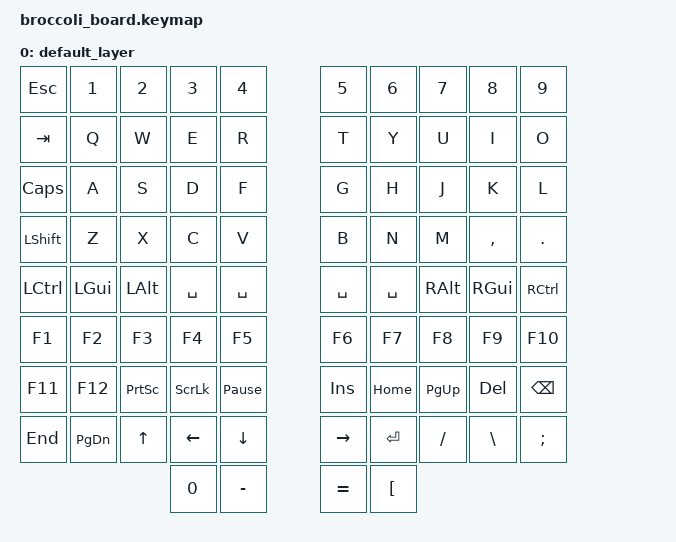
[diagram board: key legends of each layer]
#include <behaviors.dtsi>
#include <dt-bindings/zmk/keys.h>

/ {
    keymap {
        compatible = "zmk,keymap";
        default_layer {
            bindings = 
                &kp ESC &kp N1 &kp N2 &kp N3 &kp N4 &kp N5 &kp N6 &kp N7 &kp N8 &kp N9
                &kp TAB &kp Q &kp W &kp E &kp R &kp T &kp Y &kp U &kp I &kp O
                &kp CAPS &kp A &kp S &kp D &kp F &kp G &kp H &kp J &kp K &kp L
                &kp LSHFT &kp Z &kp X &kp C &kp V &kp B &kp N &kp M &kp COMMA &kp DOT
                &kp LCTRL &kp LGUI &kp LALT &kp SPACE &kp SPACE &kp SPACE &kp SPACE &kp RALT &kp RGUI &kp RCTRL
                &kp F1 &kp F2 &kp F3 &kp F4 &kp F5 &kp F6 &kp F7 &kp F8 &kp F9 &kp F10
                &kp F11 &kp F12 &kp PSCRN &kp SLCK &kp PAUSE_BREAK &kp INS &kp HOME &kp PG_UP &kp DEL &kp BSPC
                &kp END &kp PG_DN &kp UP &kp LEFT &kp DOWN &kp RIGHT &kp RET &kp FSLH &kp BSLH &kp SEMI
                &kp N0 &kp MINUS &kp EQUAL &kp LBKT
            >;
        };
    };
};

